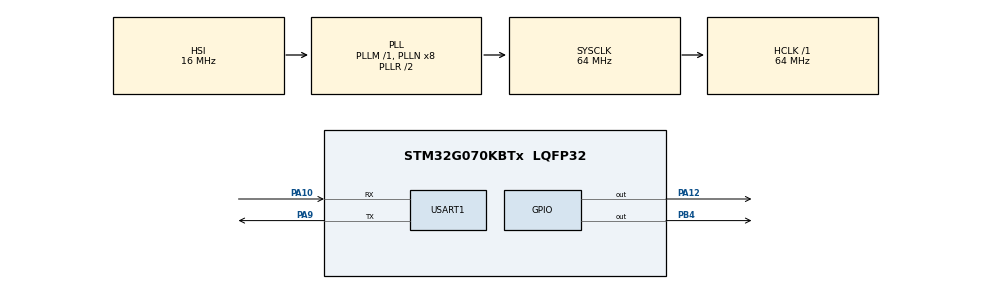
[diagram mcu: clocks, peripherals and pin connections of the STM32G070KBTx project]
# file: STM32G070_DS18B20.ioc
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Mcu.Family=STM32G0
Mcu.Name=STM32G070KBTx
Mcu.Package=LQFP32
PA10.Mode=Asynchronous
PA10.Signal=USART1_RX
PA12\ [PA10].Signal=GPIO_Output
PA13.Mode=Serial_Wire
PA13.Signal=SYS_SWDIO
PA14-BOOT0.Mode=Serial_Wire
PA14-BOOT0.Signal=SYS_SWCLK
PA9.Mode=Asynchronous
PA9.Signal=USART1_TX
PB4.Signal=GPIO_Output
PC14-OSC32_IN\ (PC14).Mode=LSE-External-Oscillator
PC14-OSC32_IN\ (PC14).Signal=RCC_OSC32_IN
PC15-OSC32_OUT\ (PC15).Mode=LSE-External-Oscillator
PC15-OSC32_OUT\ (PC15).Signal=RCC_OSC32_OUT
ProjectManager.HeapSize=0x200
ProjectManager.StackSize=0x400
ProjectManager.TargetToolchain=Makefile
RCC.ADCFreq_Value=64000000
RCC.AHBFreq_Value=64000000
RCC.CortexFreq_Value=64000000
RCC.EXTERNAL_CLOCK_VALUE=48000
RCC.HCLKFreq_Value=64000000
RCC.HSE_VALUE=8000000
RCC.HSI_VALUE=16000000
RCC.SYSCLKFreq_VALUE=64000000
RCC.SYSCLKSource=RCC_SYSCLKSOURCE_PLLCLK
RCC.VCOOutputFreq_Value=128000000
USART1.VirtualMode-Asynchronous=VM_ASYNC
VP_SYS_VS_DBSignals.Mode=DisableDeadBatterySignals
board=custom

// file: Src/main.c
/* USER CODE BEGIN Header */
/**
  ******************************************************************************
  * @file           : main.c
  * @brief          : Main program body
  ******************************************************************************
  * @attention
  *
  * <h2><center>&copy; Copyright (c) 2020 STMicroelectronics.
  * All rights reserved.</center></h2>
  *
  * This software component is licensed by ST under BSD 3-Clause license,
  * the "License"; You may not use this file except in compliance with the
  * License. You may obtain a copy of the License at:
  *                        opensource.org/licenses/BSD-3-Clause
  *
  ******************************************************************************
  */
/* USER CODE END Header */

#include "main.h"
#include "usart.h"
#include "gpio.h"

/* USER CODE BEGIN Includes */
#include "ds18b20.h"
/* USER CODE END Includes */

/* USER CODE BEGIN PV */
	uint16_t temp = 0;
/* USER CODE END PV */

void SystemClock_Config(void);

int main(void)
{

  /* MCU Configuration--------------------------------------------------------*/

  /* Reset of all peripherals, Initializes the Flash interface and the Systick. */
  HAL_Init();

  /* Configure the system clock */
  SystemClock_Config();

  /* Initialize all configured peripherals */
  MX_GPIO_Init();
  MX_USART1_UART_Init();
  /* USER CODE BEGIN 2 */
	temp =DS18B20_Init();
	printf("DS18B20_Init=%d\n",temp);
	while(0x10 == temp) ;			//获取不到正确的HCLK频率
	while(0 != temp) ;				//ds18b20初始化失败（ds18b20不存在/定时器使用的频率不对/ds18b20没有响应）
  /* USER CODE END 2 */

  /* Infinite loop */
  while (1)
  {

    /* USER CODE BEGIN 3 */
		temp = DS18B20_Get_Temp();
		printf("%d.%d\n",temp/10,temp%10);
		delay_tim_ms(500);

  }
  /* USER CODE END 3 */
}

void SystemClock_Config(void)
{
  RCC_OscInitTypeDef RCC_OscInitStruct = {0};
  RCC_ClkInitTypeDef RCC_ClkInitStruct = {0};
  RCC_PeriphCLKInitTypeDef PeriphClkInit = {0};

  /** Configure the main internal regulator output voltage
  */
  HAL_PWREx_ControlVoltageScaling(PWR_REGULATOR_VOLTAGE_SCALE1);
  /** Initializes the CPU, AHB and APB busses clocks
  */
  RCC_OscInitStruct.OscillatorType = RCC_OSCILLATORTYPE_HSI;
  RCC_OscInitStruct.HSIState = RCC_HSI_ON;
  RCC_OscInitStruct.HSIDiv = RCC_HSI_DIV1;
  RCC_OscInitStruct.HSICalibrationValue = RCC_HSICALIBRATION_DEFAULT;
  RCC_OscInitStruct.PLL.PLLState = RCC_PLL_ON;
  RCC_OscInitStruct.PLL.PLLSource = RCC_PLLSOURCE_HSI;
  RCC_OscInitStruct.PLL.PLLM = RCC_PLLM_DIV1;
  RCC_OscInitStruct.PLL.PLLN = 8;
  RCC_OscInitStruct.PLL.PLLP = RCC_PLLP_DIV2;
  RCC_OscInitStruct.PLL.PLLR = RCC_PLLR_DIV2;
  if (HAL_RCC_OscConfig(&RCC_OscInitStruct) != HAL_OK)
  {
    Error_Handler();
  }
  /** Initializes the CPU, AHB and APB busses clocks
  */
  RCC_ClkInitStruct.ClockType = RCC_CLOCKTYPE_HCLK|RCC_CLOCKTYPE_SYSCLK
                              |RCC_CLOCKTYPE_PCLK1;
  RCC_ClkInitStruct.SYSCLKSource = RCC_SYSCLKSOURCE_PLLCLK;
  RCC_ClkInitStruct.AHBCLKDivider = RCC_SYSCLK_DIV1;
  RCC_ClkInitStruct.APB1CLKDivider = RCC_HCLK_DIV1;

  if (HAL_RCC_ClockConfig(&RCC_ClkInitStruct, FLASH_LATENCY_2) != HAL_OK)
  {
    Error_Handler();
  }
  /** Initializes the peripherals clocks
  */
  PeriphClkInit.PeriphClockSelection = RCC_PERIPHCLK_USART1;
  PeriphClkInit.Usart1ClockSelection = RCC_USART1CLKSOURCE_PCLK1;
  if (HAL_RCCEx_PeriphCLKConfig(&PeriphClkInit) != HAL_OK)
  {
    Error_Handler();
  }
}

void Error_Handler(void)
{
}

/************************ (C) COPYRIGHT STMicroelectronics *****END OF FILE****/
